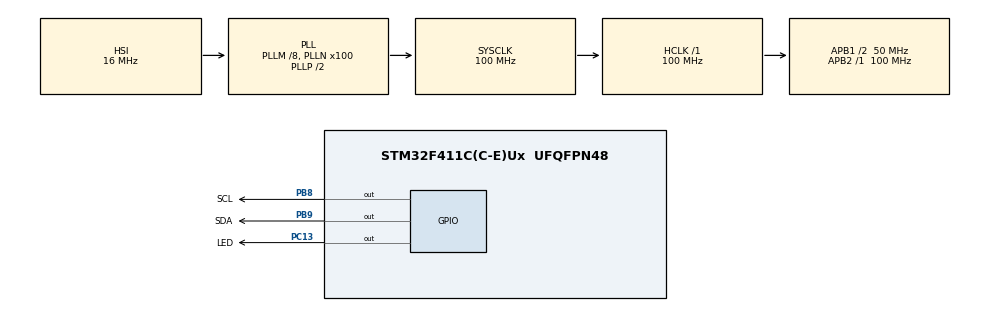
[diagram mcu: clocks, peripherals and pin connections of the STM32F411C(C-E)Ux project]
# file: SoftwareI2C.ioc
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Mcu.Family=STM32F4
Mcu.Name=STM32F411C(C-E)Ux
Mcu.Package=UFQFPN48
NVIC.PriorityGroup=NVIC_PRIORITYGROUP_4
PA13.Mode=Serial_Wire
PA13.Signal=SYS_JTMS-SWDIO
PA14.Mode=Serial_Wire
PA14.Signal=SYS_JTCK-SWCLK
PB8.GPIO_Label=SCL
PB8.Signal=GPIO_Output
PB9.GPIO_Label=SDA
PB9.Signal=GPIO_Output
PC13-ANTI_TAMP.GPIO_Label=LED
PC13-ANTI_TAMP.Signal=GPIO_Output
PH0\ -\ OSC_IN.Mode=HSE-External-Oscillator
PH0\ -\ OSC_IN.Signal=RCC_OSC_IN
PH1\ -\ OSC_OUT.Mode=HSE-External-Oscillator
PH1\ -\ OSC_OUT.Signal=RCC_OSC_OUT
ProjectManager.HeapSize=0x200
ProjectManager.StackSize=0x400
ProjectManager.TargetToolchain=STM32CubeIDE
RCC.48MHZClocksFreq_Value=50000000
RCC.AHBFreq_Value=100000000
RCC.APB1CLKDivider=RCC_HCLK_DIV2
RCC.APB1Freq_Value=50000000
RCC.APB1TimFreq_Value=100000000
RCC.APB2Freq_Value=100000000
RCC.APB2TimFreq_Value=100000000
RCC.CortexFreq_Value=100000000
RCC.HCLKFreq_Value=100000000
RCC.HSE_VALUE=25000000
RCC.HSI_VALUE=16000000
RCC.LSE_VALUE=32768
RCC.PLLM=8
RCC.PLLN=100
RCC.SYSCLKFreq_VALUE=100000000
RCC.SYSCLKSource=RCC_SYSCLKSOURCE_PLLCLK
RCC.VCOOutputFreq_Value=200000000
board=custom

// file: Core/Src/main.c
/* USER CODE BEGIN Header */
/**
  ******************************************************************************
  * @file           : main.c
  * @brief          : Main program body
  ******************************************************************************
  * @attention
  *
  * Copyright (c) 2025 STMicroelectronics.
  * All rights reserved.
  *
  * This software is licensed under terms that can be found in the LICENSE file
  * in the root directory of this software component.
  * If no LICENSE file comes with this software, it is provided AS-IS.
  *
  ******************************************************************************
  */
/* USER CODE END Header */
#include "main.h"

/* USER CODE BEGIN Includes */
#include "i2c_manager.h"
/* USER CODE END Includes */

/* USER CODE BEGIN PD */
#define TSL2561_ADDR_WRITE  0x72
#define TSL2561_ADDR_READ   0x73
#define CMD_BIT             0x80
/* USER CODE END PD */

/* USER CODE BEGIN PV */
uint16_t data = 0;
/* USER CODE END PV */

void SystemClock_Config(void);
static void MX_GPIO_Init(void);

/* USER CODE BEGIN PFP */
void TSL2561_PowerOn(void);
uint16_t TSL2561_ReadData(void);
/* USER CODE END PFP */

int main(void)
{

  /* MCU Configuration--------------------------------------------------------*/

  /* Reset of all peripherals, Initializes the Flash interface and the Systick. */
  HAL_Init();

  /* Configure the system clock */
  SystemClock_Config();

  /* Initialize all configured peripherals */
  MX_GPIO_Init();
  /* USER CODE BEGIN 2 */
  I2C_Init(GPIOB, SDA_Pin, SCL_Pin);
  TSL2561_PowerOn();
  /* USER CODE END 2 */

  /* Infinite loop */
  while (1)
  {
    /* USER CODE BEGIN 3 */
	  data = TSL2561_ReadData();
	  HAL_Delay(2000);
  }
  /* USER CODE END 3 */
}

void SystemClock_Config(void)
{
  RCC_OscInitTypeDef RCC_OscInitStruct = {0};
  RCC_ClkInitTypeDef RCC_ClkInitStruct = {0};

  /** Configure the main internal regulator output voltage
  */
  __HAL_RCC_PWR_CLK_ENABLE();
  __HAL_PWR_VOLTAGESCALING_CONFIG(PWR_REGULATOR_VOLTAGE_SCALE1);

  /** Initializes the RCC Oscillators according to the specified parameters
  * in the RCC_OscInitTypeDef structure.
  */
  RCC_OscInitStruct.OscillatorType = RCC_OSCILLATORTYPE_HSI;
  RCC_OscInitStruct.HSIState = RCC_HSI_ON;
  RCC_OscInitStruct.HSICalibrationValue = RCC_HSICALIBRATION_DEFAULT;
  RCC_OscInitStruct.PLL.PLLState = RCC_PLL_ON;
  RCC_OscInitStruct.PLL.PLLSource = RCC_PLLSOURCE_HSI;
  RCC_OscInitStruct.PLL.PLLM = 8;
  RCC_OscInitStruct.PLL.PLLN = 100;
  RCC_OscInitStruct.PLL.PLLP = RCC_PLLP_DIV2;
  RCC_OscInitStruct.PLL.PLLQ = 4;
  if (HAL_RCC_OscConfig(&RCC_OscInitStruct) != HAL_OK)
  {
    Error_Handler();
  }

  /** Initializes the CPU, AHB and APB buses clocks
  */
  RCC_ClkInitStruct.ClockType = RCC_CLOCKTYPE_HCLK|RCC_CLOCKTYPE_SYSCLK
                              |RCC_CLOCKTYPE_PCLK1|RCC_CLOCKTYPE_PCLK2;
  RCC_ClkInitStruct.SYSCLKSource = RCC_SYSCLKSOURCE_PLLCLK;
  RCC_ClkInitStruct.AHBCLKDivider = RCC_SYSCLK_DIV1;
  RCC_ClkInitStruct.APB1CLKDivider = RCC_HCLK_DIV2;
  RCC_ClkInitStruct.APB2CLKDivider = RCC_HCLK_DIV1;

  if (HAL_RCC_ClockConfig(&RCC_ClkInitStruct, FLASH_LATENCY_3) != HAL_OK)
  {
    Error_Handler();
  }
}

static void MX_GPIO_Init(void)
{
  GPIO_InitTypeDef GPIO_InitStruct = {0};

  /* GPIO Ports Clock Enable */
  __HAL_RCC_GPIOC_CLK_ENABLE();
  __HAL_RCC_GPIOH_CLK_ENABLE();
  __HAL_RCC_GPIOA_CLK_ENABLE();
  __HAL_RCC_GPIOB_CLK_ENABLE();

  /*Configure GPIO pin Output Level */
  HAL_GPIO_WritePin(LED_GPIO_Port, LED_Pin, GPIO_PIN_RESET);

  /*Configure GPIO pin Output Level */
  HAL_GPIO_WritePin(GPIOB, SCL_Pin|SDA_Pin, GPIO_PIN_RESET);

  /*Configure GPIO pin : LED_Pin */
  GPIO_InitStruct.Pin = LED_Pin;
  GPIO_InitStruct.Mode = GPIO_MODE_OUTPUT_PP;
  GPIO_InitStruct.Pull = GPIO_NOPULL;
  GPIO_InitStruct.Speed = GPIO_SPEED_FREQ_LOW;
  HAL_GPIO_Init(LED_GPIO_Port, &GPIO_InitStruct);

  /*Configure GPIO pins : SCL_Pin SDA_Pin */
  GPIO_InitStruct.Pin = SCL_Pin|SDA_Pin;
  GPIO_InitStruct.Mode = GPIO_MODE_OUTPUT_PP;
  GPIO_InitStruct.Pull = GPIO_NOPULL;
  GPIO_InitStruct.Speed = GPIO_SPEED_FREQ_LOW;
  HAL_GPIO_Init(GPIOB, &GPIO_InitStruct);

}

/* USER CODE BEGIN 4 */
void TSL2561_PowerOn(void) {
    I2C_Start();
    I2C_WriteByte(TSL2561_ADDR_WRITE);
    I2C_WriteByte(CMD_BIT | 0x00);
    I2C_WriteByte(0x03);
    I2C_Stop();
}

uint16_t TSL2561_ReadData(void) {
    uint8_t low, high;

    I2C_Start();
    I2C_WriteByte(TSL2561_ADDR_WRITE);
    I2C_WriteByte(CMD_BIT | 0x0C);
    I2C_Start();
    I2C_WriteByte(TSL2561_ADDR_READ);
    low = I2C_ReadByte(1);
    high = I2C_ReadByte(0);
    I2C_Stop();

    return (high << 8) | low;
  }
/* USER CODE END 4 */

void Error_Handler(void)
{
  __disable_irq();
  while (1)
  {
  }
}
